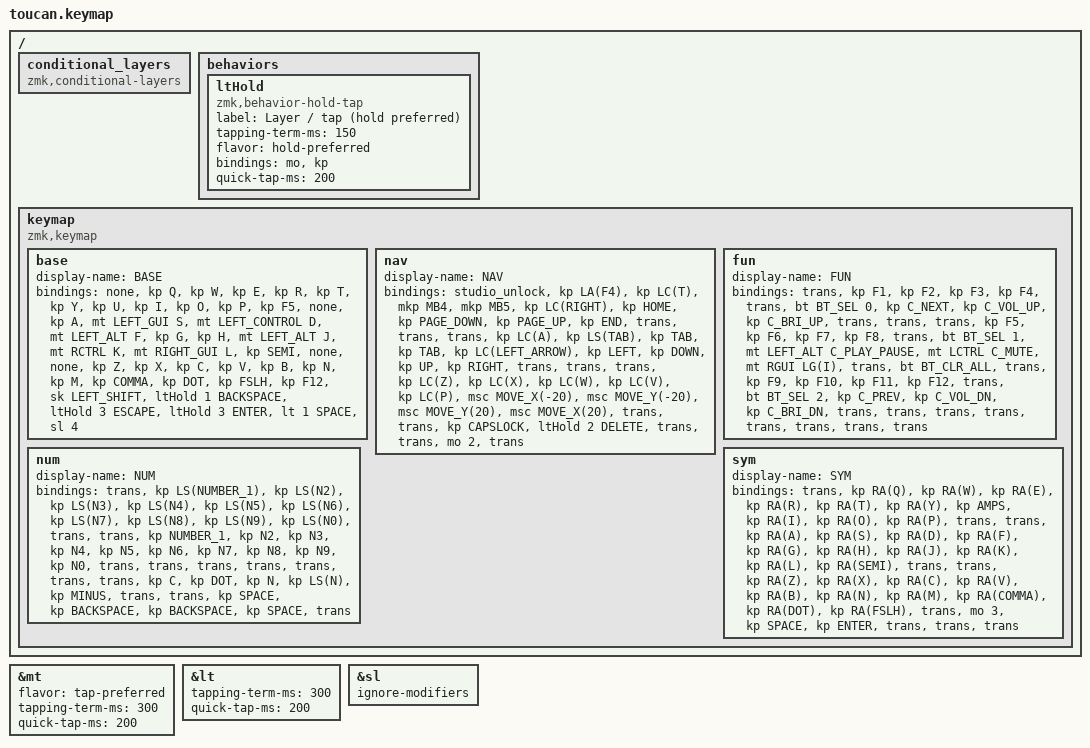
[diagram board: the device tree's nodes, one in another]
#include <behaviors.dtsi>
#include <dt-bindings/zmk/bt.h>
#include <dt-bindings/zmk/keys.h>
#include <dt-bindings/zmk/pointing.h>

#define BASE 0
#define NAV  1
#define SYM  2
#define ADJ  3

&mt {
    flavor = "tap-preferred";
    tapping-term-ms = <300>;
    quick-tap-ms = <200>;
};

&lt {
    tapping-term-ms = <300>;
    quick-tap-ms = <200>;
};

&sl { ignore-modifiers; };

/ {
    conditional_layers { compatible = "zmk,conditional-layers"; };

    behaviors {
        ltHold: ltHold {
            compatible = "zmk,behavior-hold-tap";
            label = "Layer / tap (hold preferred)";
            #binding-cells = <2>;
            tapping-term-ms = <150>;
            flavor = "hold-preferred";
            bindings = <&mo>, <&kp>;

            quick-tap-ms = <200>;
        };
    };

    keymap {
        compatible = "zmk,keymap";

        base {
            display-name = "BASE";
            bindings = <
&none  &kp Q  &kp W  &kp E  &kp R  &kp T  &kp Y  &kp U  &kp I  &kp O  &kp P  &kp F5  &none  &kp A  &mt LEFT_GUI S  &mt LEFT_CONTROL D  &mt LEFT_ALT F  &kp G  &kp H  &mt LEFT_ALT J  &mt RCTRL K  &mt RIGHT_GUI L  &kp SEMI  &none  &none  &kp Z  &kp X  &kp C  &kp V  &kp B  &kp N  &kp M  &kp COMMA  &kp DOT  &kp FSLH  &kp F12  &sk LEFT_SHIFT  &ltHold 1 BACKSPACE  &ltHold 3 ESCAPE  &ltHold 3 ENTER  &lt 1 SPACE  &sl 4
            >;
        };

        nav {
            display-name = "NAV";
            bindings = <
&studio_unlock  &kp LA(F4)  &kp LC(T)  &mkp MB4  &mkp MB5  &kp LC(RIGHT)  &kp HOME  &kp PAGE_DOWN  &kp PAGE_UP  &kp END  &trans  &trans  &trans  &kp LC(A)  &kp LS(TAB)  &kp TAB  &kp TAB  &kp LC(LEFT_ARROW)  &kp LEFT  &kp DOWN  &kp UP  &kp RIGHT  &trans  &trans  &trans  &kp LC(Z)  &kp LC(X)  &kp LC(W)  &kp LC(V)  &kp LC(P)  &msc MOVE_X(-20)  &msc MOVE_Y(-20)  &msc MOVE_Y(20)  &msc MOVE_X(20)  &trans  &trans  &kp CAPSLOCK  &ltHold 2 DELETE  &trans  &trans  &mo 2  &trans
            >;
        };

        fun {
            display-name = "FUN";
            bindings = <
&trans  &kp F1  &kp F2  &kp F3  &kp F4  &trans  &bt BT_SEL 0  &kp C_NEXT  &kp C_VOL_UP  &kp C_BRI_UP  &trans  &trans  &trans  &kp F5  &kp F6  &kp F7  &kp F8  &trans  &bt BT_SEL 1  &mt LEFT_ALT C_PLAY_PAUSE  &mt LCTRL C_MUTE  &mt RGUI LG(I)  &trans  &bt BT_CLR_ALL  &trans  &kp F9  &kp F10  &kp F11  &kp F12  &trans  &bt BT_SEL 2  &kp C_PREV  &kp C_VOL_DN  &kp C_BRI_DN  &trans  &trans  &trans  &trans  &trans  &trans  &trans  &trans
            >;
        };

        num {
            display-name = "NUM";
            bindings = <
&trans  &kp LS(NUMBER_1)  &kp LS(N2)  &kp LS(N3)  &kp LS(N4)  &kp LS(N5)  &kp LS(N6)  &kp LS(N7)  &kp LS(N8)  &kp LS(N9)  &kp LS(N0)  &trans  &trans  &kp NUMBER_1  &kp N2  &kp N3  &kp N4  &kp N5  &kp N6  &kp N7  &kp N8  &kp N9  &kp N0  &trans  &trans  &trans  &trans  &trans  &trans  &trans  &kp C  &kp DOT  &kp N  &kp LS(N)  &kp MINUS  &trans  &trans  &kp SPACE  &kp BACKSPACE  &kp BACKSPACE  &kp SPACE  &trans
            >;
        };

        sym {
            display-name = "SYM";
            bindings = <
&trans  &kp RA(Q)  &kp RA(W)  &kp RA(E)  &kp RA(R)  &kp RA(T)  &kp RA(Y)  &kp AMPS  &kp RA(I)  &kp RA(O)  &kp RA(P)  &trans  &trans  &kp RA(A)  &kp RA(S)  &kp RA(D)  &kp RA(F)  &kp RA(G)  &kp RA(H)  &kp RA(J)  &kp RA(K)  &kp RA(L)  &kp RA(SEMI)  &trans  &trans  &kp RA(Z)  &kp RA(X)  &kp RA(C)  &kp RA(V)  &kp RA(B)  &kp RA(N)  &kp RA(M)  &kp RA(COMMA)  &kp RA(DOT)  &kp RA(FSLH)  &trans  &mo 3  &kp SPACE  &kp ENTER  &trans  &trans  &trans
            >;
        };
    };
};
